# MEC1703 register map
Vendor: Microchip Technology; Series: MEC1703; File version: 0
CPU: CM4 r1p0, little endian, MPU, FPU, 3 interrupt priority bits
Registers are 32-bit, read-write, reset 0x0 unless marked. A register's access mark holds for its fields unless they carry their own. Offsets are from the block's base; [hi:lo] are bit positions; {n}, {i} and the like mark numbered series.

## PCR — The Power, Clocks, and Resets (PCR) Section identifies all the power supplies, clock sources, and reset inputs to the chip and defines all the derived power, clock, and reset signals.
Base 0x40080100; register names take the prefix PCR_
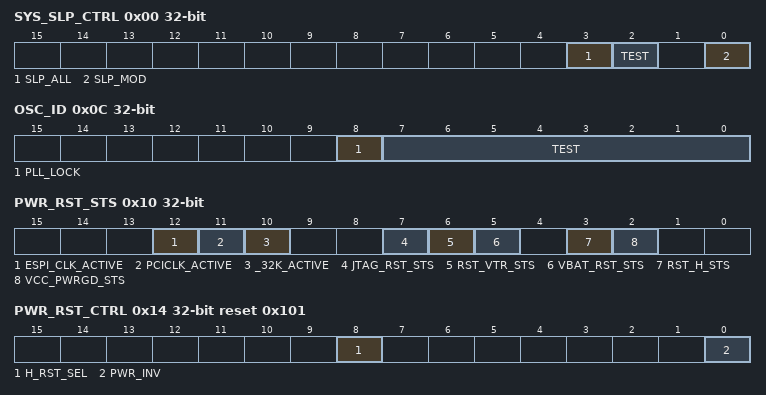
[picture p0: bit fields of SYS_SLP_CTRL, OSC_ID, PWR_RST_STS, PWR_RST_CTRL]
0x00 SYS_SLP_CTRL — System Sleep Control
  [3] SLP_ALL — Initiates the System Sleep mode
  [2] TEST — Test bit
  [0] SLP_MOD — Selects the System Sleep mode
0x04 PROC_CLK_CTRL reset 0x4 — Processor Clock Control Register [7:0] Processor Clock Divide Value (PROC_DIV). 1: divide 48 MHz Ring Oscillator by 1. 3: divide 48 MHz Ring Oscillator by 3. 4: divide 48 MHz Ring Oscillator by 4. 16: divide 48 MHz Ring Oscillator by 16. 48: divide 48 MHz Ring Oscillator by 48. No other values are supported.
  [7:0] DIV — Selects the EC clock rate
    1=DIV_BY_1 (1: divide 48 MHz Ring Oscillator by 1); 3=DIV_BY_3 (3: divide 48 MHz Ring Oscillator by 3); 4=DIV_BY_4 (4: divide 48 MHz Ring Oscillator by 4); 16=DIV_BY_16 (16: divide 48 MHz Ring Oscillator by 16); 48=DIV_BY_48 (48: divide 48 MHz Ring Oscillator by 48)
0x08 SLOW_CLK_CTRL reset 0x1E0 — Configures the EC_CLK clock domain
  [9:0] DIV — DIV. n=Divide by n; 0=Clock off
0x0C OSC_ID — Oscillator ID Register
  [8] PLL_LOCK — PLL Lock Status
  [7:0] TEST — Test bits
0x10 PWR_RST_STS — PCR Power Reset Status Register
  [12] ESPI_CLK_ACTIVE
  [11] PCICLK_ACTIVE
  [10] _32K_ACTIVE
  [7] JTAG_RST_STS — Indicates s RESET_SYS was triggered by a JTAG action.(R/WC). 0 = No JTAG reset occurred since the last time this bit was cleared. 1 = A reset occurred because of a JATAG command.
  [6] RST_VTR_STS — Indicates the status of VTR_RESET.(R/WC). 0 = No reset occurred since the last time this bit was cleared. 1 = A reset occurred.
  [5] VBAT_RST_STS — VBAT reset status 0 = No reset occurred while VTR was off or since the last time this bit was cleared. 1 = A reset occurred.(R/WC)
  [3] RST_H_STS — Indicates the status of RESET_VCC. 0 = reset active. 1 = reset not active.
  [2] VCC_PWRGD_STS — Indicates the status of VCC_PWRGD. 0 = PWRGD not asserted. 1 = PWRGD asserte.
0x14 PWR_RST_CTRL reset 0x101 — Power Reset Control Register
  [8] H_RST_SEL — Determines what generates the internal platform reset signal. 1=LRESET# pin; 0=eSPI PLTRST# VWire
  [0] PWR_INV — Used by FW to control internal RESET_VCC signal function and external PWROK pin. This bit is read-only when VCC_PWRGD is de-asserted low.
0x18 SYS_RST — System Reset Register
  [8] SOFT_SYS_RST — A write of a 1 forces an assertion of the RESET_SYS reset signal, resetting the device. A write of 0 has no effect.
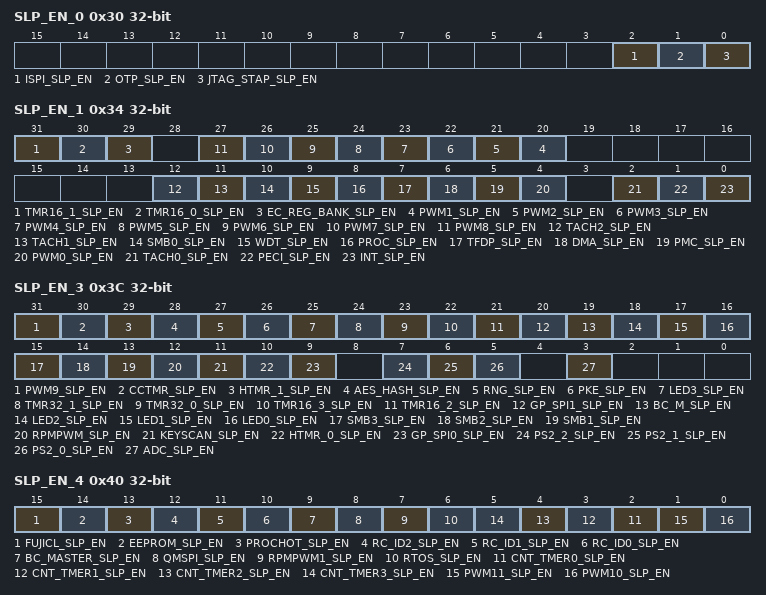
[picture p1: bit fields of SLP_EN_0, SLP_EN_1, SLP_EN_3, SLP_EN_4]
0x30 SLP_EN_0 — Sleep Enable 0 Register
  [2] ISPI_SLP_EN — ISPI Enable
  [1] OTP_SLP_EN — eFuse Enable
  [0] JTAG_STAP_SLP_EN — JTAG STAP Enable
0x34 SLP_EN_1 — Sleep Enable 1 Register
  [31] TMR16_1_SLP_EN — TIMER16_1 Sleep Enable
  [30] TMR16_0_SLP_EN — TIMER16_0 Sleep Enable
  [29] EC_REG_BANK_SLP_EN — EC_REG_BANK Sleep Enable
  [n+19] PWM{n}_SLP_EN (n=1..8) — PWM{n} Sleep Enable
  [12] TACH2_SLP_EN — TACH2 Sleep Enable
  [11] TACH1_SLP_EN — TACH1 Sleep Enable
  [10] SMB0_SLP_EN — SMB0 Sleep Enable
  [9] WDT_SLP_EN — WDT Sleep Enable
  [8] PROC_SLP_EN — PROCESSOR Sleep Enable
  [7] TFDP_SLP_EN — TFDP Sleep Enable
  [6] DMA_SLP_EN — DMA Sleep Enable
  [5] PMC_SLP_EN — PMC Sleep Enable
  [4] PWM0_SLP_EN — PWM0 Sleep Enable
  [2] TACH0_SLP_EN — TACH0 Sleep Enable
  [1] PECI_SLP_EN — PECI Sleep Enable
  [0] INT_SLP_EN — Interrupt Sleep Enable
0x38 SLP_EN_2 — Sleep Enable 2 Register
  [26] PORT80_1_SLP_EN — Port80 1 Sleep Enable
  [25] PORT80_0_SLP_EN — Port80 0 Sleep Enable
  [23] ACPI_EC_4_SLP_EN — ACPI EC 4 Sleep Enable
  [22] ACPI_EC_3_SLP_EN — ACPI EC 3 Sleep Enable
  [21] ACPI_EC_2_SLP_EN — ACPI EC 2 Sleep Enable
  [19] ESPI_SLP_EN — eSPI Sleep Enable
  [18] RTC_SLP_EN — RTC Sleep Enable
  [17] MBOX_SLP_EN — Mailbox Sleep Enable
  [16] EMU_8042_SLP_EN — 8042 Emulation Sleep Enable
  [16] KBCEM_SLP_EN — 8042EM Sleep Enable (8042EM_SLP_EN)
  [15] ACPI_PM1_SLP_EN — ACPI PM1 Sleep Enable
  [14] ACPI_EC_1_SLP_EN — ACPI EC 1 Sleep Enable
  [13] ACPI_EC_0_SLP_EN — ACPI EC 0 Sleep Enable
  [12] GLBL_CFG_SLP_EN — GLBL_CFG
  [2] UART1_SLP_EN — UART 1 Sleep Enable
  [1] UART0_SLP_EN — UART 0 Sleep Enable
  [0] LPC_SLP_EN — LPC Sleep Enable
0x3C SLP_EN_3 — Sleep Enable 3 Register
  [31] PWM9_SLP_EN — PWM9 Sleep Enable
  [30] CCTMR_SLP_EN — Capture Compare Timer Sleep Enable
  [29] HTMR_1_SLP_EN — HTIMER 1 Sleep Enable
  [28] AES_HASH_SLP_EN — AES_HASH Sleep Enable
  [27] RNG_SLP_EN — RNG Sleep Enable
  [26] PKE_SLP_EN — PKE Sleep Enable
  [25] LED3_SLP_EN — LED3 Sleep Enable
  [24] TMR32_1_SLP_EN — TIMER32_1 Sleep Enable
  [23] TMR32_0_SLP_EN — TIMER32_0 Sleep Enable
  [22] TMR16_3_SLP_EN — TIMER16_3 Sleep Enable
  [21] TMR16_2_SLP_EN — TIMER16_2_Sleep Enable
  [20] GP_SPI1_SLP_EN — GP SPI1 Sleep Enable
  [19] BC_M_SLP_EN — BC Master Sleep Enable
  [18] LED2_SLP_EN — LED2 Sleep Enable
  [17] LED1_SLP_EN — LED1 Sleep Enable
  [16] LED0_SLP_EN — LED0 Sleep Enable
  [15] SMB3_SLP_EN — SMB3 Sleep Enable
  [14] SMB2_SLP_EN — SMB2 Sleep Enable
  [13] SMB1_SLP_EN — SMB1 Sleep Enable
  [12] RPMPWM_SLP_EN — RPM-PWM Sleep Enable
  [11] KEYSCAN_SLP_EN — KEYSCAN Sleep Enable
  [10] HTMR_0_SLP_EN — HTIMER 0 Sleep Enable
  [9] GP_SPI0_SLP_EN — GP SPI0 Sleep Enable
  [7] PS2_2_SLP_EN — PS2 2 Sleep Enable
  [6] PS2_1_SLP_EN — PS2 1 Sleep Enable
  [5] PS2_0_SLP_EN — PS2 0 Sleep Enable
  [3] ADC_SLP_EN — ADC Sleep Enable
0x40 SLP_EN_4 — Sleep Enable 4 Register
  [15] FUJICL_SLP_EN — Fujitsu Custom Logic Sleep Enable
  [14] EEPROM_SLP_EN — EEPROM Sleep Enable
  [13] PROCHOT_SLP_EN — PROCHOT Sleep Enable
  [12] RC_ID2_SLP_EN — RC_ID2 Sleep Enable
  [11] RC_ID1_SLP_EN — RC_ID1 Sleep Enable
  [10] RC_ID0_SLP_EN — RC_ID0 Sleep Enable
  [9] BC_MASTER_SLP_EN — BC Master Sleep Enable
  [8] QMSPI_SLP_EN — Quad SPI Sleep Enable
  [7] RPMPWM1_SLP_EN — RPMPWM 1 Sleep Enable
  [6] RTOS_SLP_EN — PWM6 Sleep Enable
  [n+2] CNT_TMER{n}_SLP_EN (n=0..3) — CNT_TMER{n} Sleep Enable
  [1] PWM11_SLP_EN — PWM11 Sleep Enable
  [0] PWM10_SLP_EN — PWM10 Sleep Enable
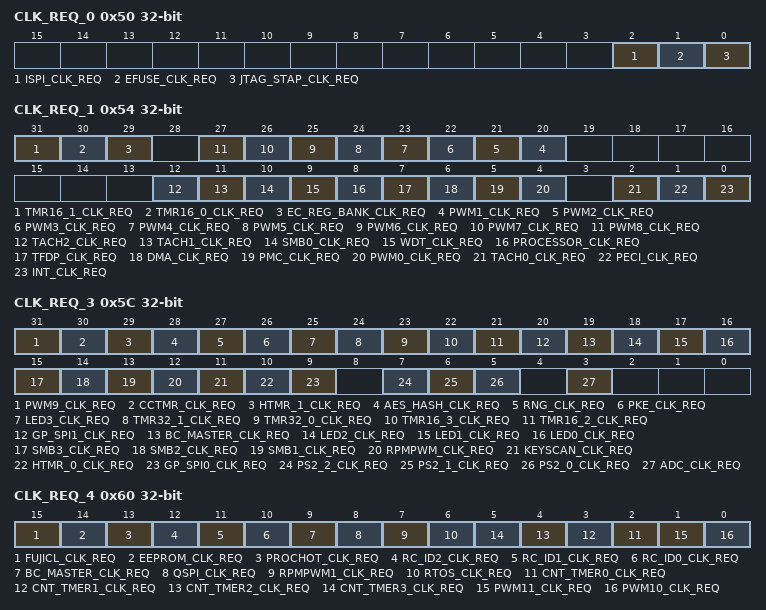
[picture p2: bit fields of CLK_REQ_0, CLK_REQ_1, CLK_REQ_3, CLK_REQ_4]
0x50 CLK_REQ_0 — Clock Required 0 Register
  [2] ISPI_CLK_REQ — ISPI Clock Reuqired
  [1] EFUSE_CLK_REQ — eFuse Clock Reuqired
  [0] JTAG_STAP_CLK_REQ — JTAG Clock Reuqired
0x54 CLK_REQ_1 — Clock Required 1 Register
  [31] TMR16_1_CLK_REQ — TIMER16_1 Clock Reuqired
  [30] TMR16_0_CLK_REQ — TIMER16_0 Clock Reuqired
  [29] EC_REG_BANK_CLK_REQ — EC_REG_BANK Clock Reuqired
  [n+19] PWM{n}_CLK_REQ (n=1..8) — PWM{n} Clock Reuqired
  [12] TACH2_CLK_REQ — TACH2 Clock Reuqired
  [11] TACH1_CLK_REQ — TACH1 Clock Reuqired
  [10] SMB0_CLK_REQ — SMB0 Clock Reuqired
  [9] WDT_CLK_REQ — WDT Clock Reuqired
  [8] PROCESSOR_CLK_REQ — PROCESSOR Clock Reuqired
  [7] TFDP_CLK_REQ — TFDP Clock Reuqired
  [6] DMA_CLK_REQ — DMA Clock Reuqired
  [5] PMC_CLK_REQ — PMC Clock Reuqired
  [4] PWM0_CLK_REQ — PWM0 Clock Reuqired
  [2] TACH0_CLK_REQ — TACH0 Clock Reuqired
  [1] PECI_CLK_REQ — PECI Clock Reuqired
  [0] INT_CLK_REQ — Interrupt Clock Reuqired
0x58 CLK_REQ_2 — Clock Required 2 Register
  [26] PORT80_1_CLK_REQ — Port80 1 Clock Reuqired
  [25] PORT80_0_CLK_REQ — Port80 0 Clock Reuqired
  [23] ACPI_EC_4_CLK_REQ — ACPI EC 4 Clock Reuqired
  [22] ACPI_EC_3_CLK_REQ — ACPI EC 3 Clock Reuqired
  [21] ACPI_EC_2_CLK_REQ — ACPI EC 2 Clock Reuqired
  [19] ESPI_CLK_REQ — eSPI Clock Reuqired
  [18] RTC_CLK_REQ — RTC Clock Reuqired
  [17] MAILBOX_CLK_REQ — Mailbox Clock Reuqired
  [16] EMU_8042_CLK_REQ — 8042 Emulation Clock Reuqired
  [16] KBCEM_CLK_REQ — 8042EM Clock Reuqired (8042EM_CLK_REQ)
  [15] ACPI_PM1_CLK_REQ — ACPI PM1 Clock Reuqired
  [14] ACPI_EC_1_CLK_REQ — ACPI EC 1 Clock Reuqired
  [13] ACPI_EC_0_CLK_REQ — ACPI EC 0 Clock Reuqired
  [12] GLBL_CFG_CLK_REQ — GLBL_CFG Clock Reuqired
  [2] UART_1_CLK_REQ — UART 1 Clock Reuqired
  [1] UART_0_CLK_REQ — UART 0 Clock Reuqired
  [0] LPC_CLK_REQ — LPC Clock Reuqired
0x5C CLK_REQ_3 — Clock Required 3 Register
  [31] PWM9_CLK_REQ — PWM9 Clock Reuqired
  [30] CCTMR_CLK_REQ — Capture Compare Timer Clock Reuqired
  [29] HTMR_1_CLK_REQ — HTIMER 1 Clock Reuqired
  [28] AES_HASH_CLK_REQ — AES_HASH Clock Reuqired
  [27] RNG_CLK_REQ — RNG Clock Reuqired
  [26] PKE_CLK_REQ — PKE Clock Reuqired
  [25] LED3_CLK_REQ — LED3 Clock Reuqired
  [24] TMR32_1_CLK_REQ — TIMER32_1 Clock Reuqired
  [23] TMR32_0_CLK_REQ — TIMER32_0 Clock Reuqired
  [22] TMR16_3_CLK_REQ — TIMER16_3 Clock Reuqired
  [21] TMR16_2_CLK_REQ — TIMER16_2 Clock Reuqired
  [20] GP_SPI1_CLK_REQ — GP SPI1 Clock Reuqired
  [19] BC_MASTER_CLK_REQ — BC Master Clock Reuqired
  [18] LED2_CLK_REQ — LED2 Clock Reuqired
  [17] LED1_CLK_REQ — LED1 Clock Reuqired
  [16] LED0_CLK_REQ — LED0 Clock Reuqired
  [15] SMB3_CLK_REQ — SMB3 Clock Reuqired
  [14] SMB2_CLK_REQ — SMB2 Clock Reuqired
  [13] SMB1_CLK_REQ — SMB1 Clock Reuqired
  [12] RPMPWM_CLK_REQ — RPM-PWM Clock Reuqired
  [11] KEYSCAN_CLK_REQ — KEYSCAN Clock Reuqired
  [10] HTMR_0_CLK_REQ — HTIMER 0 Clock Reuqired
  [9] GP_SPI0_CLK_REQ — GP SPI0 Clock Reuqired
  [7] PS2_2_CLK_REQ — PS2 2 Clock Reuqired
  [6] PS2_1_CLK_REQ — PS2 1 Clock Reuqired
  [5] PS2_0_CLK_REQ — PS2 0 Clock Reuqired
  [3] ADC_CLK_REQ — ADC Clock Reuqired
0x60 CLK_REQ_4 — Clock Required 4 Register
  [15] FUJICL_CLK_REQ — Fujitsu Custom Logic Clock Reuqired
  [14] EEPROM_CLK_REQ — EEPROM Clock Reuqired
  [13] PROCHOT_CLK_REQ — PROCHOT Clock Reuqired
  [12] RC_ID2_CLK_REQ — RC_ID2 Clock Reuqired
  [11] RC_ID1_CLK_REQ — RC_ID1 Clock Reuqired
  [10] RC_ID0_CLK_REQ — RC_ID0 Clock Reuqired
  [9] BC_MASTER_CLK_REQ — BC Master Clock Reuqired
  [8] QSPI_CLK_REQ — Quad SPI Clock Reuqired
  [7] RPMPWM1_CLK_REQ — RPMPWM 1 Clock Reuqired
  [6] RTOS_CLK_REQ — PWM6 Clock Reuqired
  [n+2] CNT_TMER{n}_CLK_REQ (n=0..3) — CNT_TMER{n} Clock Reuqired
  [1] PWM11_CLK_REQ — PWM11 Clock Reuqired
  [0] PWM10_CLK_REQ — PWM10 Clock Reuqired
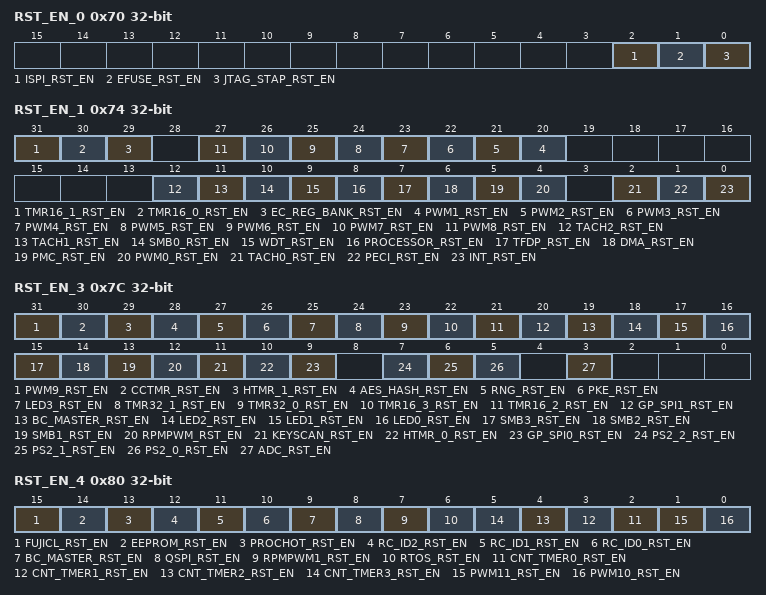
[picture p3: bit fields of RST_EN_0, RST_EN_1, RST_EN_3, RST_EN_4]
0x70 RST_EN_0 — Reset Enable 0 Register
  [2] ISPI_RST_EN — ISPI Reset Enable
  [1] EFUSE_RST_EN — eFuse Reset Enable
  [0] JTAG_STAP_RST_EN — JTAG STAP Reset Enable
0x74 RST_EN_1 — Reset Enable 1 Register
  [31] TMR16_1_RST_EN — TIMER16_1 Reset Enable
  [30] TMR16_0_RST_EN — TIMER16_0 Reset Enable
  [29] EC_REG_BANK_RST_EN — EC_REG_BANK Reset Enable
  [n+19] PWM{n}_RST_EN (n=1..8) — PWM{n} Reset Enable
  [12] TACH2_RST_EN — TACH2 Reset Enable
  [11] TACH1_RST_EN — TACH1 Reset Enable
  [10] SMB0_RST_EN — SMB0 Reset Enable
  [9] WDT_RST_EN — WDT Reset Enable
  [8] PROCESSOR_RST_EN — PROCESSOR Reset Enable
  [7] TFDP_RST_EN — TFDP Reset Enable
  [6] DMA_RST_EN — DMA Reset Enable
  [5] PMC_RST_EN — PMC Reset Enable
  [4] PWM0_RST_EN — PWM0 Reset Enable
  [2] TACH0_RST_EN — TACH0 Reset Enable
  [1] PECI_RST_EN — PECI Reset Enable
  [0] INT_RST_EN — Interrupt Reset Enable
0x78 RST_EN_2 — Reset Enable 2 Register
  [26] PORT80_1_RST_EN — Port80 1 Reset Enable
  [25] PORT80_0_RST_EN — Port80 0 Reset Enable
  [23] ACPI_EC_4_RST_EN — ACPI EC 4 Reset Enable
  [22] ACPI_EC_3_RST_EN — ACPI EC 3 Reset Enable
  [21] ACPI_EC_2_RST_EN — ACPI EC 2 Reset Enable
  [19] ESPI_RST_EN — eSPI Reset Enable
  [18] RTC_RST_EN — RTC Reset Enable
  [17] MAILBOX_RST_EN — Mailbox Reset Enable
  [16] EMU_8042_RST_EN — 8042 Emulation Reset Enable
  [16] KBCEM_RST_EN — 8042EM Reset Enable (8042EM_RST_EN)
  [15] ACPI_PM1_RST_EN — ACPI PM1 Reset Enable
  [14] ACPI_EC_1_RST_EN — ACPI EC 1 Reset Enable
  [13] ACPI_EC_0_RST_EN — ACPI EC 0 Reset Enable
  [12] GLBL_CFG_RST_EN — GLBL_CFG Reset Enable
  [2] UART_1_RST_EN — UART 1 Reset Enable
  [1] UART_0_RST_EN — UART 0 Reset Enable
  [0] LPC_RST_EN — LPC Reset Enable
0x7C RST_EN_3 — Reset Enable 3 Register
  [31] PWM9_RST_EN — PWM9 Reset Enable
  [30] CCTMR_RST_EN — Capture Compare Timer Reset Enable
  [29] HTMR_1_RST_EN — HTIMER 1 Reset Enable
  [28] AES_HASH_RST_EN — AES_HASH Reset Enable
  [27] RNG_RST_EN — RNG Reset Enable
  [26] PKE_RST_EN — PKE Reset Enable
  [25] LED3_RST_EN — LED3 Reset Enable
  [24] TMR32_1_RST_EN — TIMER32_1 Reset Enable
  [23] TMR32_0_RST_EN — TIMER32_0 Reset Enable
  [22] TMR16_3_RST_EN — TIMER16_3 Reset Enable
  [21] TMR16_2_RST_EN — TIMER16_2 Reset Enable
  [20] GP_SPI1_RST_EN — GP SPI1 Reset Enable
  [19] BC_MASTER_RST_EN — BC Master Reset Enable
  [18] LED2_RST_EN — LED2 Reset Enable
  [17] LED1_RST_EN — LED1 Reset Enable
  [16] LED0_RST_EN — LED0 Reset Enable
  [15] SMB3_RST_EN — SMB3 Reset Enable
  [14] SMB2_RST_EN — SMB2 Reset Enable
  [13] SMB1_RST_EN — SMB1 Reset Enable
  [12] RPMPWM_RST_EN — RPM-PWM Reset Enable
  [11] KEYSCAN_RST_EN — KEYSCAN Reset Enable
  [10] HTMR_0_RST_EN — HTIMER 0 Reset Enable
  [9] GP_SPI0_RST_EN — GP SPI0 Reset Enable
  [7] PS2_2_RST_EN — PS2 2 Reset Enable
  [6] PS2_1_RST_EN — PS2 1 Reset Enable
  [5] PS2_0_RST_EN — PS2 0 Reset Enable
  [3] ADC_RST_EN — ADC Reset Enable
0x80 RST_EN_4 — Reset Enable 4 Register
  [15] FUJICL_RST_EN — Fujitsu Custom Logic Reset Enable
  [14] EEPROM_RST_EN — EEPROM Reset Enable
  [13] PROCHOT_RST_EN — PROCHOT Reset Enable
  [12] RC_ID2_RST_EN — RC_ID2 Reset Enable
  [11] RC_ID1_RST_EN — RC_ID1 Reset Enable
  [10] RC_ID0_RST_EN — RC_ID0 Reset Enable
  [9] BC_MASTER_RST_EN — BC Master Reset Enable
  [8] QSPI_RST_EN — Quad SPI Reset Enable
  [7] RPMPWM1_RST_EN — RPMPWM 1 Reset Enable
  [6] RTOS_RST_EN — PWM6 Reset Enable
  [n+2] CNT_TMER{n}_RST_EN (n=0..3) — CNT_TMER{n} Reset Enable
  [1] PWM11_RST_EN — PWM11 Reset Enable
  [0] PWM10_RST_EN — PWM10 Reset Enable

## Notices in the file
Copyright (c) 2017 Microchip Technology Inc.
SPDX-License-Identifier: Apache-2.0
Licensed under the Apache License, Version 2.0 (the "License");
you may not use this file except in compliance with the License.
You may obtain a copy of the License at
http://www.apache.org/licenses/LICENSE-2.0
Unless required by applicable law or agreed to in writing, software
distributed under the License is distributed on an "AS IS" BASIS,
WITHOUT WARRANTIES OR CONDITIONS OF ANY KIND, either express or implied.
See the License for the specific language governing permissions and
limitations under the License.
